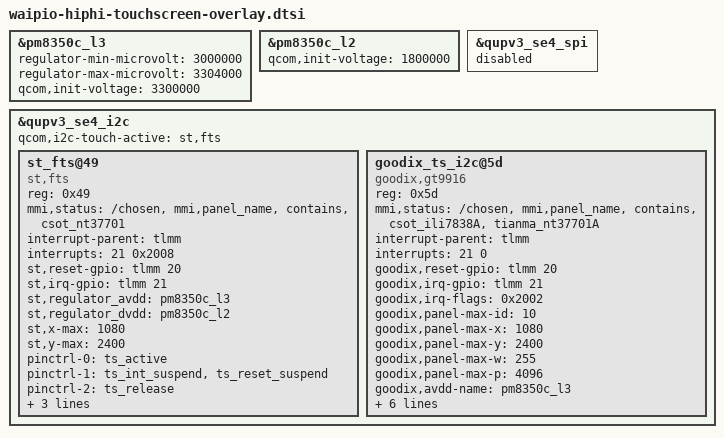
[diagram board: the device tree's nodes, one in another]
/*
 * Copyright (c) 2019, The Linux Foundation. All rights reserved.
 *
 * This program is free software; you can redistribute it and/or modify
 * it under the terms of the GNU General Public License version 2 and
 * only version 2 as published by the Free Software Foundation.
 *
 * This program is distributed in the hope that it will be useful,
 * but WITHOUT ANY WARRANTY; without even the implied warranty of
 * MERCHANTABILITY or FITNESS FOR A PARTICULAR PURPOSE.  See the
 * GNU General Public License for more details.
 */

&pm8350c_l3 {
	regulator-min-microvolt = <3000000>;
	regulator-max-microvolt = <3304000>;
	qcom,init-voltage = <3300000>;
};

&pm8350c_l2 {
	qcom,init-voltage = <1800000>;
};

&qupv3_se4_spi {
	status = "disabled";
};

&qupv3_se4_i2c {
	#address-cells = <1>;
	#size-cells = <0>;

	status = "ok";
	qcom,i2c-touch-active = "st,fts";

	st_fts@49 {
		compatible = "st,fts";
		reg = <0x49>;
		mmi,status = "/chosen","mmi,panel_name","contains","csot_nt37701";
		interrupt-parent = <&tlmm>;
		interrupts = <21 0x2008>;
		st,reset-gpio = <&tlmm 20 0>;
		st,irq-gpio = <&tlmm 21 0x2008>;
		st,regulator_avdd = "pm8350c_l3";
		st,regulator_dvdd = "pm8350c_l2";
		st,x-max = <1080>;
		st,y-max = <2400>;
		pinctrl-names = "pmx_ts_active", "pmx_ts_suspend", "pmx_ts_release";
		pinctrl-0 = <&ts_active>;
		pinctrl-1 = <&ts_int_suspend &ts_reset_suspend>;
		pinctrl-2 = <&ts_release>;
		mmi,enable-gestures;
		mmi,power-off-suspend;
		mmi,usb-charger-detection;
	};

	goodix_ts_i2c@5d {
		compatible = "goodix,gt9916";
		reg = <0x5d>;
		mmi,status = "/chosen","mmi,panel_name","contains","csot_ili7838A","tianma_nt37701A";
		interrupt-parent = <&tlmm>;
		interrupts = <21 0>;
		goodix,reset-gpio = <&tlmm 20 0x0>;
		goodix,irq-gpio = <&tlmm 21 0x2002>;
		goodix,irq-flags = <0x2002>; /* 1:trigger rising, 2:trigger falling;*/
		goodix,panel-max-id = <10>;
		goodix,panel-max-x = <1080>;
		goodix,panel-max-y = <2400>;
		goodix,panel-max-w = <255>;
		goodix,panel-max-p = <4096>;
		goodix,avdd-name = "pm8350c_l3";
		goodix,iovdd-name = "pm8350c_l2";
		goodix,pen-enable;
		pinctrl-names = "pmx_ts_active", "pmx_ts_suspend", "pmx_ts_release";
		pinctrl-0 = <&ts_active>;
		pinctrl-1 = <&ts_int_suspend &ts_reset_suspend>;
		pinctrl-2 = <&ts_release>;
		mmi,power-off-suspend;
	};
};
